# ESP32S31_RADIO register map
Vendor: Espressif; Series: ESP32-S31; File version: 3.52
Registers are 32-bit, read-write, no defined reset value unless marked. A register's access mark holds for its fields unless they carry their own. Offsets are from the block's base; [hi:lo] are bit positions; {n}, {i} and the like mark numbered series.

## WIFI_MAC_CONTROL — Shared MAC run/stop control. The cold open-RX frontier publishes zero; the complete vendor channel-switch chain requests quiescence here and later restarts the no-power-save profile.
Base 0x20104CAC
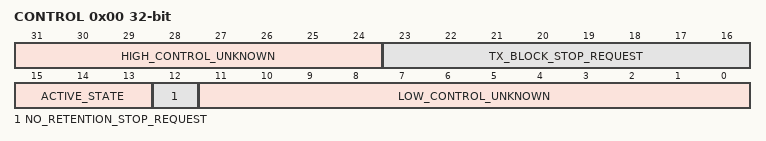
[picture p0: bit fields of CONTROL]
0x00 CONTROL — Cold promiscuous initialization writes zero. hal_mac_deinit records bits 13 and 14 as TX/RX activity and sets bit 12 plus bits 23:16; hal_mac_init with WIFI_PS_NONE clears that same stop-request mask.
  [31:24] HIGH_CONTROL_UNKNOWN
  [23:16] TX_BLOCK_STOP_REQUEST — Eight stop-request bits selected from the WIFI_PS_NONE TX-block retention mask by hal_mac_deinit and cleared by hal_mac_init.
    on write: 0=RUN_ALL (Clear every no-power-save TX block stop request.); 255=STOP_ALL (Request every no-power-save TX block to stop before retuning.)
  [15:13] ACTIVE_STATE ro — Three-bit activity state polled until zero before PHY retuning. hal_mac_deinit independently records bit 13 as TX active and bit 14 as RX active; bit 15 remains unnamed.
  [12] NO_RETENTION_STOP_REQUEST — Included in the MAC stop request and cleared by hal_mac_init for the WIFI_PS_NONE all-ones retention mask.
  [11:0] LOW_CONTROL_UNKNOWN

## WIFI_MAC_REGDMA_CONTROL — Shared WDEVPWR control word. The channel-change leaf proves the REGDMA selector, while complete modem-power leaves prove the wake-protect lead time and TBTT auto-period fields. Hardware interactions between these fields remain unqualified.
Base 0x2010D83C
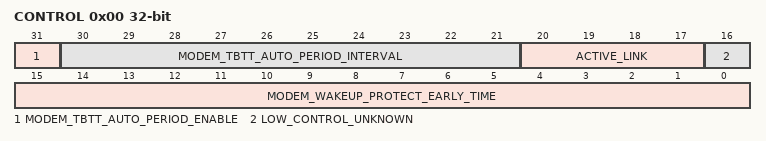
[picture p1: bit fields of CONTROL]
0x00 CONTROL — Shared REGDMA and modem wakeup configuration word. Every promoted field has a complete independent setter; their combined hardware lifecycle is not inferred.
  [31] MODEM_TBTT_AUTO_PERIOD_ENABLE — The dedicated enable and disable leaves set or clear bit 31.
  [30:21] MODEM_TBTT_AUTO_PERIOD_INTERVAL — pwr_hal_set_mac_modem_tbtt_auto_period_interval replaces bits 30:21 from the low ten argument bits.
  [20:17] ACTIVE_LINK — Four-bit Wi-Fi MAC REGDMA link selector; the active no-power-save channel restart writes four. Leaving zero after retuning caused intermittent authentication ACK timeouts.
    on write: 4=WIFI_NO_POWER_SAVE (REGDMA link selected by the qualified Wi-Fi no-power-save restart.)
  [16] LOW_CONTROL_UNKNOWN
  [15:0] MODEM_WAKEUP_PROTECT_EARLY_TIME — pwr_hal_set_mac_modem_state_wakeup_protect_early_time replaces the low sixteen bits.

## WIFI_MAC_CRYPTO_CONTROL — Per-interface hardware-crypto controls, shared policy mask and key validity bitmap recovered from complete libpp hal_crypto leaves.
Base 0x20104800
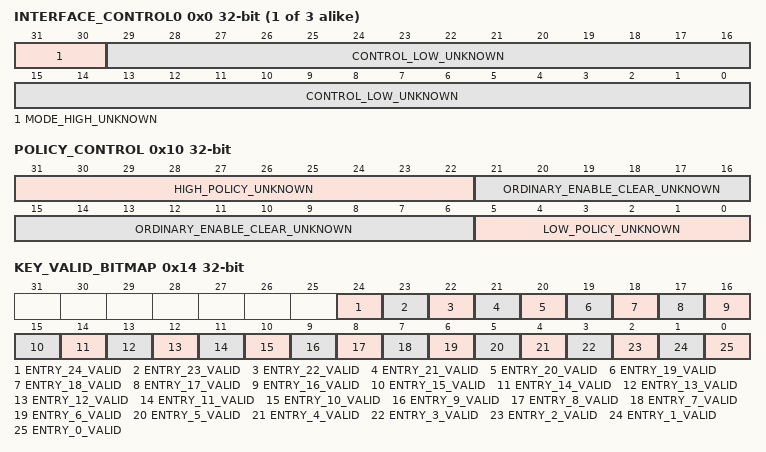
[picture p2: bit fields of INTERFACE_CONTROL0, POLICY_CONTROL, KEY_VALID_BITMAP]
{0x0+4i} INTERFACE_CONTROL{i} (i=0..2) — STA, AP and NAN interface controls selected by hal_crypto_enable. The open STA CCMP path writes the complete image 0x00030103, then clears bits 31:30.
  [31:30] MODE_HIGH_UNKNOWN — Complete ordinary enable clears both high bits; one algorithm branch sets bit 31.
  [29:0] CONTROL_LOW_UNKNOWN — Algorithm, enable and management-frame policy fields composed by the complete leaf; individual electrical meanings remain partly unknown.
0x0C INIT_AUX_UNKNOWN — Fourth full-word cold-init store, cleared by complete hal_crypto_init. Its algorithm-specific meaning is not yet recovered.
  [31:0] VALUE_UNKNOWN
0x10 POLICY_CONTROL — Shared policy word. The ordinary non-algorithm-four enable path preserves bits 31:22 and 5:0 while clearing bits 21:6.
  [31:22] HIGH_POLICY_UNKNOWN
  [21:6] ORDINARY_ENABLE_CLEAR_UNKNOWN — Cleared by the reachable STA CCMP enable transaction.
  [5:0] LOW_POLICY_UNKNOWN
0x14 KEY_VALID_BITMAP — One validity bit per one of the 25 evidenced hardware key entries.
  [24] ENTRY_24_VALID — Validity of key-table entry twenty-four.
  [23] ENTRY_23_VALID — Validity of key-table entry twenty-three.
  [22] ENTRY_22_VALID — Validity of key-table entry twenty-two.
  [21] ENTRY_21_VALID — Validity of key-table entry twenty-one.
  [20] ENTRY_20_VALID — Validity of key-table entry twenty.
  [19] ENTRY_19_VALID — Validity of key-table entry nineteen.
  [18] ENTRY_18_VALID — Validity of key-table entry eighteen.
  [17] ENTRY_17_VALID — Validity of key-table entry seventeen.
  [16] ENTRY_16_VALID — Validity of key-table entry sixteen.
  [15] ENTRY_15_VALID — Validity of key-table entry fifteen.
  [14] ENTRY_14_VALID — Validity of key-table entry fourteen.
  [13] ENTRY_13_VALID — Validity of key-table entry thirteen.
  [12] ENTRY_12_VALID — Validity of key-table entry twelve.
  [11] ENTRY_11_VALID — Validity of key-table entry eleven.
  [10] ENTRY_10_VALID — Validity of key-table entry ten.
  [9] ENTRY_9_VALID — Validity of key-table entry nine.
  [8] ENTRY_8_VALID — Validity of key-table entry eight.
  [7] ENTRY_7_VALID — Validity of key-table entry seven.
  [6] ENTRY_6_VALID — Validity of key-table entry six.
  [5] ENTRY_5_VALID — Validity of key-table entry five.
  [4] ENTRY_4_VALID — Validity of key-table entry four.
  [3] ENTRY_3_VALID — Validity of key-table entry three.
  [2] ENTRY_2_VALID — Validity of key-table entry two.
  [1] ENTRY_1_VALID — Validity of key-table entry one.
  [0] ENTRY_0_VALID — Validity of key-table entry zero.
